AUTOSAR XML (schema 4-0-3)
standard types defined: UInt32, UInt8
package /AUTOSAR_Platform/DataConstrs
  range DC_UInt8: raw 0..255
package /PATAC/MSM/ComponentTypes
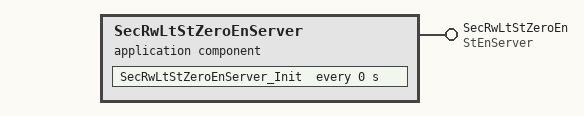
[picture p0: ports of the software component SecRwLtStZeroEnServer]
  application sw component type SecRwLtStZeroEnServer
    provide port SecRwLtStZeroEn: provided-com-specs=[{operation=Clear, queue-length=1}, {operation=Get, queue-length=1}, {operation=Set, queue-length=1}], provided-interface=StEnServer
    behavior SecRwLtStZeroEnServer_InternalBehavior
      operation invoked event OIT_SecRwLtStZeroEn_Clear_SecRwLtStZeroEn_Clear: start-on-event=SecRwLtStZeroEn_Clear, operation=SecRwLtStZeroEn.Clear
      operation invoked event OIT_SecRwLtStZeroEn_Get_SecRwLtStZeroEn_Get: start-on-event=SecRwLtStZeroEn_Get, operation=SecRwLtStZeroEn.Get
      operation invoked event OIT_SecRwLtStZeroEn_Set_SecRwLtStZeroEn_Set: start-on-event=SecRwLtStZeroEn_Set, operation=SecRwLtStZeroEn.Set
      timing event SecRwLtStZeroEnServer_InitEvent: start-on-event=SecRwLtStZeroEnServer_Init, period=0
      4 x runnable:
        SecRwLtStZeroEn_Clear
        SecRwLtStZeroEn_Get
        SecRwLtStZeroEn_Set
        SecRwLtStZeroEnServer_Init
  swc implementation SecRwLtStZeroEnServer_Implementation: behavior=SecRwLtStZeroEnServer_InternalBehavior
    code-descriptors:
      code Default: artifact-descriptors=autosar-engineering-object={short-label=Default, category=SWSRC}
package /PATAC/MSM/ModeAdjust/PortInterface
  client server interface StEnServer
    operation Clear
      arg data: type=UInt8, direction=IN, server-argument-impl-policy=USE-ARGUMENT-TYPE
    operation Get
      arg data: type=UInt32, direction=OUT, server-argument-impl-policy=USE-ARGUMENT-TYPE
    operation Set
      arg data: type=UInt8, direction=IN, server-argument-impl-policy=USE-ARGUMENT-TYPE
